# PIC32MX254F128B register map
Vendor: Microchip
Registers are 32-bit, read-write, reset 0x0 unless marked. A register's access mark holds for its fields unless they carry their own. Addresses are absolute, and some are shared; only a register's first bit layout is shown; [hi:lo] are bit positions; {n}, {i} and the like mark numbered series.

## PMP
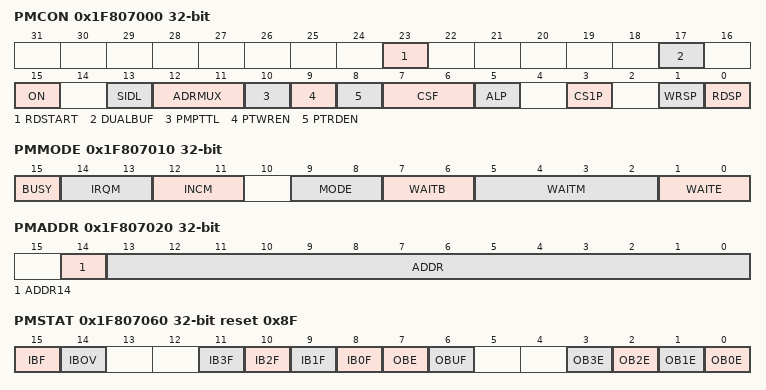
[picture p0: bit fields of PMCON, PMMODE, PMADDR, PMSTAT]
0x1F807000 PMCON reset not defined — (power-on value --------x-----x-0-000-00000-0-00)
  [23] RDSTART, [17] DUALBUF, [15] ON, [13] SIDL, [12:11] ADRMUX, [10] PMPTTL, [9] PTWREN, [8] PTRDEN, [7:6] CSF, [5] ALP, [3] CS1P, [1] WRSP, [0] RDSP
0x1F807010 PMMODE
  [15] BUSY, [14:13] IRQM, [12:11] INCM, [9:8] MODE, [7:6] WAITB, [5:2] WAITM, [1:0] WAITE
0x1F807020 PMADDR reset not defined — (power-on value -----------------xxxxxxxxxxxxxxx)
  [14] ADDR14, [13:0] ADDR
0x1F807030 PMDOUT reset not defined — (power-on value xxxxxxxxxxxxxxxxxxxxxxxxxxxxxxxx)
  [31:0] DATAOUT
0x1F807040 PMDIN reset not defined — (power-on value xxxxxxxxxxxxxxxxxxxxxxxxxxxxxxxx)
  [31:0] DATAIN
0x1F807050 PMAEN reset not defined — (power-on value --------xxxxxxxxxxxxxxxxxxxxxxxx)
  [23:0] PTEN
0x1F807060 PMSTAT reset 0x8F
  [15] IBF ro, [14] IBOV, [n+8] IB{n}F ro (n=0..3), [7] OBE ro, [6] OBUF, [n] OB{n}E ro (n=0..3)
0x1F807070 PMWADDR reset not defined — (power-on value --------xxxxxxxxxxxxxxxxxxxxxxxx)
  [23:0] WADDR
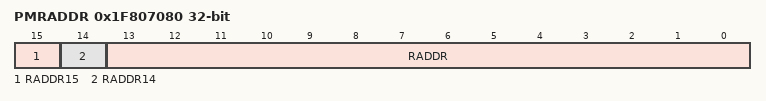
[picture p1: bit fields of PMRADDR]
0x1F807080 PMRADDR reset not defined — (power-on value ----------------xxxxxxxxxxxxxxxx)
  [15] RADDR15, [14] RADDR14, [13:0] RADDR
0x1F807090 PMRDIN reset not defined — (power-on value xxxxxxxxxxxxxxxxxxxxxxxxxxxxxxxx)
  [31:0] RDATAIN

## ADC10
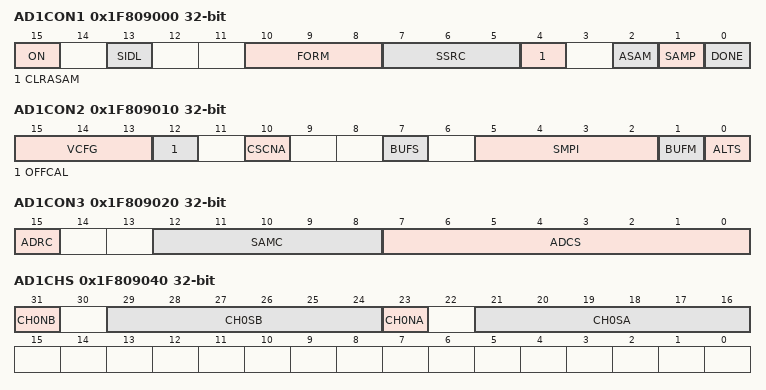
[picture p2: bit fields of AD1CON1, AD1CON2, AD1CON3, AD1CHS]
0x1F809000 AD1CON1
  [15] ON
  [13] SIDL
  [10:8] FORM
  [7:5] SSRC
  [4] CLRASAM
  [2] ASAM
  [1] SAMP
  [0] DONE — (can only be cleared)
0x1F809010 AD1CON2
  [15:13] VCFG, [12] OFFCAL, [10] CSCNA, [7] BUFS ro, [5:2] SMPI, [1] BUFM, [0] ALTS
0x1F809020 AD1CON3
  [15] ADRC, [12:8] SAMC, [7:0] ADCS
0x1F809040 AD1CHS reset not defined — (power-on value 0-xxxxxx0-xxxxxx----------------)
  [31] CH0NB, [29:24] CH0SB, [23] CH0NA, [21:16] CH0SA
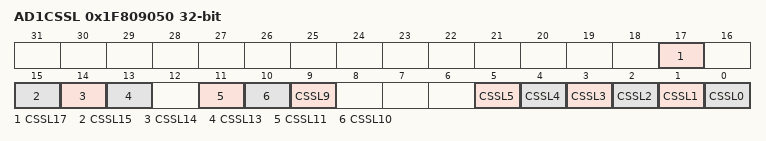
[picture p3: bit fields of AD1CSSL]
0x1F809050 AD1CSSL reset not defined — (power-on value --------------x-xxx-xxx---xxxxxx)
  [17] CSSL17, [15] CSSL15, [14] CSSL14, [13] CSSL13, [11] CSSL11, [10] CSSL10, [9] CSSL9, [n] CSSL{n} (n=0..5)
{0x1F809070+0x10*i} ADC1BUF{i} ro (i=0..9)
0x1F809110 ADC1BUFA ro
0x1F809120 ADC1BUFB ro
0x1F809130 ADC1BUFC ro
0x1F809140 ADC1BUFD ro
0x1F809150 ADC1BUFE ro
0x1F809160 ADC1BUFF ro

## CVR
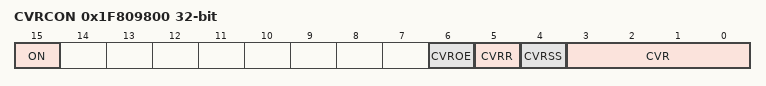
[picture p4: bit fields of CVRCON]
0x1F809800 CVRCON
  [15] ON, [6] CVROE, [5] CVRR, [4] CVRSS, [3:0] CVR

## CMP1
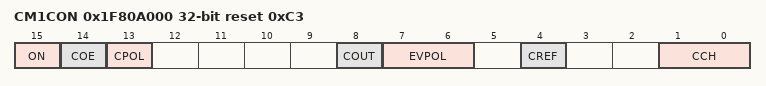
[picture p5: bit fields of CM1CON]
0x1F80A000 CM1CON reset 0xC3
  [15] ON, [14] COE, [13] CPOL, [8] COUT, [7:6] EVPOL, [4] CREF, [1:0] CCH

## CMP2
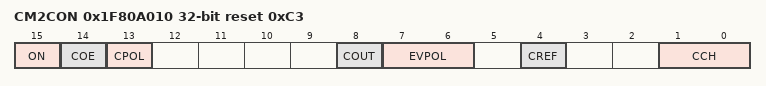
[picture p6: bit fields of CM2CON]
0x1F80A010 CM2CON reset 0xC3
  [15] ON, [14] COE, [13] CPOL, [8] COUT, [7:6] EVPOL, [4] CREF, [1:0] CCH

## CMP3
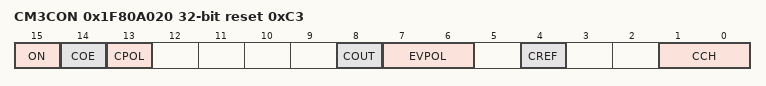
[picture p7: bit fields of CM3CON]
0x1F80A020 CM3CON reset 0xC3
  [15] ON, [14] COE, [13] CPOL, [8] COUT, [7:6] EVPOL, [4] CREF, [1:0] CCH

## cmp_control_pb
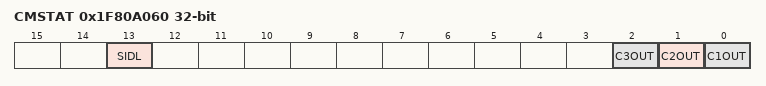
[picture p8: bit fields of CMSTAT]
0x1F80A060 CMSTAT reset not defined — (power-on value ------------------------00---x00)
  [13] SIDL, [2] C3OUT, [1] C2OUT ro, [0] C1OUT ro

## CTMU
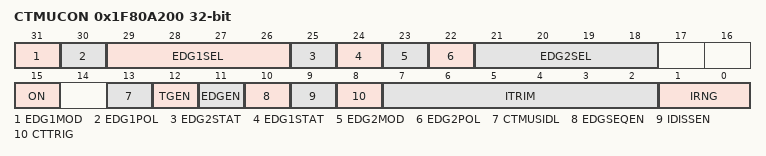
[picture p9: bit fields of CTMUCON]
0x1F80A200 CTMUCON
  [31] EDG1MOD, [30] EDG1POL, [29:26] EDG1SEL, [25] EDG2STAT, [24] EDG1STAT, [23] EDG2MOD, [22] EDG2POL, [21:18] EDG2SEL, [15] ON, [13] CTMUSIDL, [12] TGEN, [11] EDGEN, [10] EDGSEQEN, [9] IDISSEN, [8] CTTRIG, [7:2] ITRIM, [1:0] IRNG

## CRU
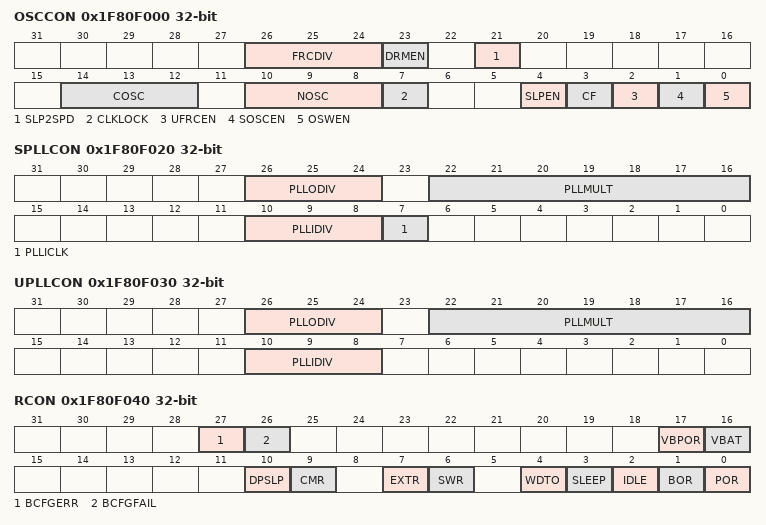
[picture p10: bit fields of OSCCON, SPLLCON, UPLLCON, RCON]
0x1F80F000 OSCCON reset not defined — (power-on value -----0000-x------000-xxx0--000x0)
  [26:24] FRCDIV, [23] DRMEN, [21] SLP2SPD, [14:12] COSC ro, [10:8] NOSC, [7] CLKLOCK, [4] SLPEN, [3] CF, [2] UFRCEN, [1] SOSCEN, [0] OSWEN
0x1F80F010 OSCTUN
  [5:0] TUN
0x1F80F020 SPLLCON reset not defined — (power-on value -----001-xxxxxxx-----xxx0-------)
  [26:24] PLLODIV, [22:16] PLLMULT, [10:8] PLLIDIV, [7] PLLICLK
0x1F80F030 UPLLCON reset not defined — (power-on value -----001-xxxxxxx-----001--------)
  [26:24] PLLODIV, [22:16] PLLMULT, [10:8] PLLIDIV
0x1F80F040 RCON reset not defined — (power-on value ----00---------------x0-00-00011)
  [27] BCFGERR, [26] BCFGFAIL, [17] VBPOR, [16] VBAT, [10] DPSLP, [9] CMR, [7] EXTR, [6] SWR, [4] WDTO, [3] SLEEP, [2] IDLE, [1] BOR, [0] POR
0x1F80F050 RSWRST wo
  [0] SWRST
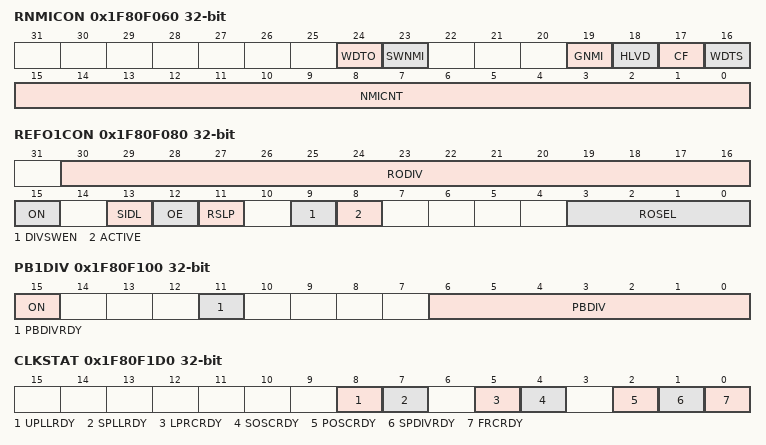
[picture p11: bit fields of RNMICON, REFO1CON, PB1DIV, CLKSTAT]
0x1F80F060 RNMICON
  [24] WDTO, [23] SWNMI, [19] GNMI, [18] HLVD, [17] CF, [16] WDTS, [15:0] NMICNT
0x1F80F070 PWRCON
  [0] VREGS
0x1F80F080 REFO1CON
  [30:16] RODIV, [15] ON, [13] SIDL, [12] OE, [11] RSLP, [9] DIVSWEN, [8] ACTIVE ro, [3:0] ROSEL
0x1F80F090 REFO1TRIM
  [31:23] ROTRIM
0x1F80F100 PB1DIV reset not defined — (power-on value ----------------1---1----xxxxxxx)
  [15] ON, [11] PBDIVRDY ro, [6:0] PBDIV
0x1F80F1D0 CLKSTAT reset not defined — (power-on value ------------------------0-00-0x0)
  [8] UPLLRDY, [7] SPLLRDY ro, [5] LPRCRDY ro, [4] SOSCRDY ro, [2] POSCRDY ro, [1] SPDIVRDY, [0] FRCRDY ro
